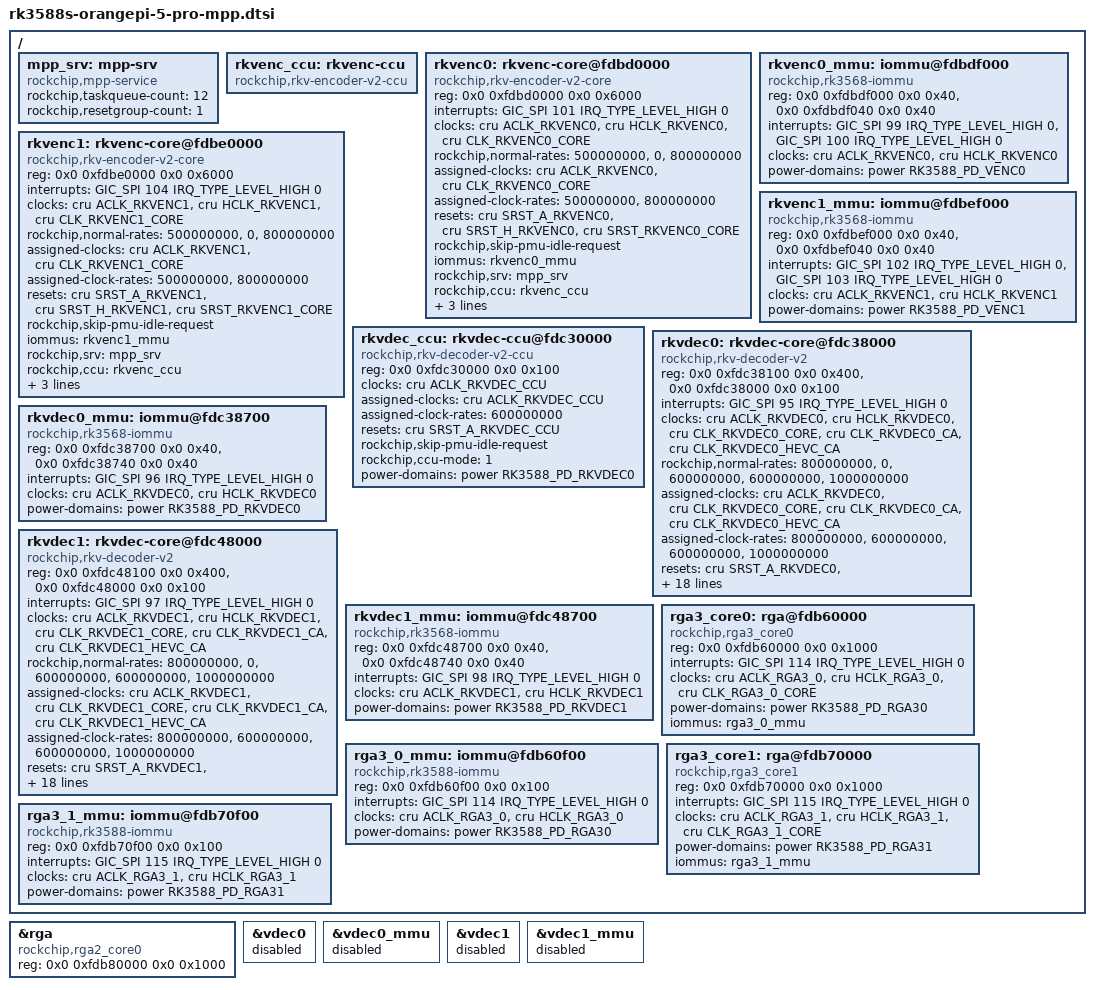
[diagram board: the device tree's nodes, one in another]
/*
 * opi5: the vendor MPP (RKVDEC2, RKVENC2) and multi-RGA nodes for the
 * zz-opi5-1xxx drivers. Included at the end of rk3588s-orangepi-5-pro.dts.
 */

/ {
	/*
	 * The rkmpp-codec profile owns these cores through Rockchip's request
	 * ABI.  Keep this binding here, rather than changing rk3588-base.dtsi:
	 * other RK3588 boards retain their upstream V4L2 topology.
	 */
	mpp_srv: mpp-srv {
		compatible = "rockchip,mpp-service";
		rockchip,taskqueue-count = <12>;
		rockchip,resetgroup-count = <1>;
		status = "okay";
	};

	rkvenc_ccu: rkvenc-ccu {
		compatible = "rockchip,rkv-encoder-v2-ccu";
		status = "okay";
	};

	rkvenc0: rkvenc-core@fdbd0000 {
		compatible = "rockchip,rkv-encoder-v2-core";
		reg = <0x0 0xfdbd0000 0x0 0x6000>;
		interrupts = <GIC_SPI 101 IRQ_TYPE_LEVEL_HIGH 0>;
		clocks = <&cru ACLK_RKVENC0>, <&cru HCLK_RKVENC0>,
			 <&cru CLK_RKVENC0_CORE>;
		clock-names = "aclk_vcodec", "hclk_vcodec", "clk_core";
		rockchip,normal-rates = <500000000>, <0>, <800000000>;
		assigned-clocks = <&cru ACLK_RKVENC0>, <&cru CLK_RKVENC0_CORE>;
		assigned-clock-rates = <500000000>, <800000000>;
		resets = <&cru SRST_A_RKVENC0>, <&cru SRST_H_RKVENC0>,
			 <&cru SRST_RKVENC0_CORE>;
		reset-names = "video_a", "video_h", "video_core";
		rockchip,skip-pmu-idle-request;
		iommus = <&rkvenc0_mmu>;
		rockchip,srv = <&mpp_srv>;
		rockchip,ccu = <&rkvenc_ccu>;
		rockchip,taskqueue-node = <7>;
		rockchip,task-capacity = <8>;
		power-domains = <&power RK3588_PD_VENC0>;
		status = "okay";
	};

	rkvenc0_mmu: iommu@fdbdf000 {
		compatible = "rockchip,rk3568-iommu";
		reg = <0x0 0xfdbdf000 0x0 0x40>, <0x0 0xfdbdf040 0x0 0x40>;
		interrupts = <GIC_SPI 99 IRQ_TYPE_LEVEL_HIGH 0>,
			     <GIC_SPI 100 IRQ_TYPE_LEVEL_HIGH 0>;
		clocks = <&cru ACLK_RKVENC0>, <&cru HCLK_RKVENC0>;
		clock-names = "aclk", "iface";
		#iommu-cells = <0>;
		power-domains = <&power RK3588_PD_VENC0>;
		status = "okay";
	};

	rkvenc1: rkvenc-core@fdbe0000 {
		compatible = "rockchip,rkv-encoder-v2-core";
		reg = <0x0 0xfdbe0000 0x0 0x6000>;
		interrupts = <GIC_SPI 104 IRQ_TYPE_LEVEL_HIGH 0>;
		clocks = <&cru ACLK_RKVENC1>, <&cru HCLK_RKVENC1>,
			 <&cru CLK_RKVENC1_CORE>;
		clock-names = "aclk_vcodec", "hclk_vcodec", "clk_core";
		rockchip,normal-rates = <500000000>, <0>, <800000000>;
		assigned-clocks = <&cru ACLK_RKVENC1>, <&cru CLK_RKVENC1_CORE>;
		assigned-clock-rates = <500000000>, <800000000>;
		resets = <&cru SRST_A_RKVENC1>, <&cru SRST_H_RKVENC1>,
			 <&cru SRST_RKVENC1_CORE>;
		reset-names = "video_a", "video_h", "video_core";
		rockchip,skip-pmu-idle-request;
		iommus = <&rkvenc1_mmu>;
		rockchip,srv = <&mpp_srv>;
		rockchip,ccu = <&rkvenc_ccu>;
		rockchip,taskqueue-node = <7>;
		rockchip,task-capacity = <8>;
		power-domains = <&power RK3588_PD_VENC1>;
		status = "okay";
	};

	rkvenc1_mmu: iommu@fdbef000 {
		compatible = "rockchip,rk3568-iommu";
		reg = <0x0 0xfdbef000 0x0 0x40>, <0x0 0xfdbef040 0x0 0x40>;
		interrupts = <GIC_SPI 102 IRQ_TYPE_LEVEL_HIGH 0>,
			     <GIC_SPI 103 IRQ_TYPE_LEVEL_HIGH 0>;
		clocks = <&cru ACLK_RKVENC1>, <&cru HCLK_RKVENC1>;
		clock-names = "aclk", "iface";
		#iommu-cells = <0>;
		power-domains = <&power RK3588_PD_VENC1>;
		status = "okay";
	};

	rkvdec_ccu: rkvdec-ccu@fdc30000 {
		compatible = "rockchip,rkv-decoder-v2-ccu";
		reg = <0x0 0xfdc30000 0x0 0x100>;
		reg-names = "ccu";
		clocks = <&cru ACLK_RKVDEC_CCU>;
		clock-names = "aclk_ccu";
		assigned-clocks = <&cru ACLK_RKVDEC_CCU>;
		assigned-clock-rates = <600000000>;
		resets = <&cru SRST_A_RKVDEC_CCU>;
		reset-names = "video_ccu";
		rockchip,skip-pmu-idle-request;
		rockchip,ccu-mode = <1>;
		power-domains = <&power RK3588_PD_RKVDEC0>;
		status = "okay";
	};

	rkvdec0: rkvdec-core@fdc38000 {
		compatible = "rockchip,rkv-decoder-v2";
		reg = <0x0 0xfdc38100 0x0 0x400>, <0x0 0xfdc38000 0x0 0x100>;
		reg-names = "regs", "link";
		interrupts = <GIC_SPI 95 IRQ_TYPE_LEVEL_HIGH 0>;
		clocks = <&cru ACLK_RKVDEC0>, <&cru HCLK_RKVDEC0>,
			 <&cru CLK_RKVDEC0_CORE>, <&cru CLK_RKVDEC0_CA>,
			 <&cru CLK_RKVDEC0_HEVC_CA>;
		clock-names = "aclk_vcodec", "hclk_vcodec", "clk_core",
			      "clk_cabac", "clk_hevc_cabac";
		rockchip,normal-rates = <800000000>, <0>, <600000000>,
					<600000000>, <1000000000>;
		assigned-clocks = <&cru ACLK_RKVDEC0>, <&cru CLK_RKVDEC0_CORE>,
				  <&cru CLK_RKVDEC0_CA>, <&cru CLK_RKVDEC0_HEVC_CA>;
		assigned-clock-rates = <800000000>, <600000000>,
				       <600000000>, <1000000000>;
		resets = <&cru SRST_A_RKVDEC0>, <&cru SRST_H_RKVDEC0>,
			 <&cru SRST_RKVDEC0_CORE>, <&cru SRST_RKVDEC0_CA>,
			 <&cru SRST_RKVDEC0_HEVC_CA>;
		reset-names = "video_a", "video_h", "video_core", "video_cabac",
			      "video_hevc_cabac";
		rockchip,skip-pmu-idle-request;
		/* Firmware reset preserves the RKVDEC2 CCU transaction. */
		rockchip,vpu-reset-smc;
		iommus = <&rkvdec0_mmu>;
		rockchip,srv = <&mpp_srv>;
		rockchip,ccu = <&rkvdec_ccu>;
		rockchip,core-mask = <0x00010001>;
		rockchip,task-capacity = <16>;
		rockchip,taskqueue-node = <9>;
		rockchip,sram = <&vdec0_sram>;
		rockchip,rcb-iova = <0xfff00000 0x100000>;
		rockchip,rcb-info = <136 24576>, <137 49152>, <141 90112>,
				    <140 49152>, <139 180224>, <133 49152>,
				    <134 8192>, <135 4352>, <138 13056>, <142 291584>;
		rockchip,rcb-min-width = <512>;
		power-domains = <&power RK3588_PD_RKVDEC0>;
		status = "okay";
	};

	rkvdec0_mmu: iommu@fdc38700 {
		compatible = "rockchip,rk3568-iommu";
		reg = <0x0 0xfdc38700 0x0 0x40>, <0x0 0xfdc38740 0x0 0x40>;
		interrupts = <GIC_SPI 96 IRQ_TYPE_LEVEL_HIGH 0>;
		clocks = <&cru ACLK_RKVDEC0>, <&cru HCLK_RKVDEC0>;
		clock-names = "aclk", "iface";
		#iommu-cells = <0>;
		power-domains = <&power RK3588_PD_RKVDEC0>;
		status = "okay";
	};

	rkvdec1: rkvdec-core@fdc48000 {
		compatible = "rockchip,rkv-decoder-v2";
		reg = <0x0 0xfdc48100 0x0 0x400>, <0x0 0xfdc48000 0x0 0x100>;
		reg-names = "regs", "link";
		interrupts = <GIC_SPI 97 IRQ_TYPE_LEVEL_HIGH 0>;
		clocks = <&cru ACLK_RKVDEC1>, <&cru HCLK_RKVDEC1>,
			 <&cru CLK_RKVDEC1_CORE>, <&cru CLK_RKVDEC1_CA>,
			 <&cru CLK_RKVDEC1_HEVC_CA>;
		clock-names = "aclk_vcodec", "hclk_vcodec", "clk_core",
			      "clk_cabac", "clk_hevc_cabac";
		rockchip,normal-rates = <800000000>, <0>, <600000000>,
					<600000000>, <1000000000>;
		assigned-clocks = <&cru ACLK_RKVDEC1>, <&cru CLK_RKVDEC1_CORE>,
				  <&cru CLK_RKVDEC1_CA>, <&cru CLK_RKVDEC1_HEVC_CA>;
		assigned-clock-rates = <800000000>, <600000000>,
				       <600000000>, <1000000000>;
		resets = <&cru SRST_A_RKVDEC1>, <&cru SRST_H_RKVDEC1>,
			 <&cru SRST_RKVDEC1_CORE>, <&cru SRST_RKVDEC1_CA>,
			 <&cru SRST_RKVDEC1_HEVC_CA>;
		reset-names = "video_a", "video_h", "video_core", "video_cabac",
			      "video_hevc_cabac";
		rockchip,skip-pmu-idle-request;
		/* Firmware reset preserves the RKVDEC2 CCU transaction. */
		rockchip,vpu-reset-smc;
		iommus = <&rkvdec1_mmu>;
		rockchip,srv = <&mpp_srv>;
		rockchip,ccu = <&rkvdec_ccu>;
		rockchip,core-mask = <0x00020002>;
		rockchip,task-capacity = <16>;
		rockchip,taskqueue-node = <9>;
		rockchip,sram = <&vdec1_sram>;
		rockchip,rcb-iova = <0xffe00000 0x100000>;
		rockchip,rcb-info = <136 24576>, <137 49152>, <141 90112>,
				    <140 49152>, <139 180224>, <133 49152>,
				    <134 8192>, <135 4352>, <138 13056>, <142 291584>;
		rockchip,rcb-min-width = <512>;
		power-domains = <&power RK3588_PD_RKVDEC1>;
		status = "okay";
	};

	rkvdec1_mmu: iommu@fdc48700 {
		compatible = "rockchip,rk3568-iommu";
		reg = <0x0 0xfdc48700 0x0 0x40>, <0x0 0xfdc48740 0x0 0x40>;
		interrupts = <GIC_SPI 98 IRQ_TYPE_LEVEL_HIGH 0>;
		clocks = <&cru ACLK_RKVDEC1>, <&cru HCLK_RKVDEC1>;
		clock-names = "aclk", "iface";
		#iommu-cells = <0>;
		power-domains = <&power RK3588_PD_RKVDEC1>;
		status = "okay";
	};

	rga3_core0: rga@fdb60000 {
		compatible = "rockchip,rga3_core0";
		reg = <0x0 0xfdb60000 0x0 0x1000>;
		interrupts = <GIC_SPI 114 IRQ_TYPE_LEVEL_HIGH 0>;
		interrupt-names = "rga3_core0_irq";
		clocks = <&cru ACLK_RGA3_0>, <&cru HCLK_RGA3_0>,
			 <&cru CLK_RGA3_0_CORE>;
		clock-names = "aclk_rga3_0", "hclk_rga3_0", "clk_rga3_0";
		power-domains = <&power RK3588_PD_RGA30>;
		iommus = <&rga3_0_mmu>;
		status = "okay";
	};

	rga3_0_mmu: iommu@fdb60f00 {
		compatible = "rockchip,rk3588-iommu", "rockchip,rk3568-iommu";
		reg = <0x0 0xfdb60f00 0x0 0x100>;
		interrupts = <GIC_SPI 114 IRQ_TYPE_LEVEL_HIGH 0>;
		interrupt-names = "rga3_0_mmu";
		clocks = <&cru ACLK_RGA3_0>, <&cru HCLK_RGA3_0>;
		clock-names = "aclk", "iface";
		power-domains = <&power RK3588_PD_RGA30>;
		#iommu-cells = <0>;
		status = "okay";
	};

	rga3_core1: rga@fdb70000 {
		compatible = "rockchip,rga3_core1";
		reg = <0x0 0xfdb70000 0x0 0x1000>;
		interrupts = <GIC_SPI 115 IRQ_TYPE_LEVEL_HIGH 0>;
		interrupt-names = "rga3_core1_irq";
		clocks = <&cru ACLK_RGA3_1>, <&cru HCLK_RGA3_1>,
			 <&cru CLK_RGA3_1_CORE>;
		clock-names = "aclk_rga3_1", "hclk_rga3_1", "clk_rga3_1";
		power-domains = <&power RK3588_PD_RGA31>;
		iommus = <&rga3_1_mmu>;
		status = "okay";
	};

	rga3_1_mmu: iommu@fdb70f00 {
		compatible = "rockchip,rk3588-iommu", "rockchip,rk3568-iommu";
		reg = <0x0 0xfdb70f00 0x0 0x100>;
		interrupts = <GIC_SPI 115 IRQ_TYPE_LEVEL_HIGH 0>;
		interrupt-names = "rga3_1_mmu";
		clocks = <&cru ACLK_RGA3_1>, <&cru HCLK_RGA3_1>;
		clock-names = "aclk", "iface";
		power-domains = <&power RK3588_PD_RGA31>;
		#iommu-cells = <0>;
		status = "okay";
	};
};

/*
 * The upstream V4L2 RGA2 node shares fdb80000 with the vendor multi-RGA
 * service.  Retarget that single node rather than creating a duplicate
 * unit-address node, then bind all three engines to one /dev/rga owner.
 */
&rga {
	compatible = "rockchip,rga2_core0";
	reg = <0x0 0xfdb80000 0x0 0x1000>;
	interrupt-names = "rga2_irq";
	clock-names = "aclk_rga2", "hclk_rga2", "clk_rga2";
	status = "okay";
};

/* The MPP binding owns the vendor decoder windows and IOMMU instances. */
&vdec0 {
	status = "disabled";
};

&vdec0_mmu {
	status = "disabled";
};

&vdec1 {
	status = "disabled";
};

&vdec1_mmu {
	status = "disabled";
};

/* Keep the MPP IOMMUs enabled after disabling the competing V4L2 nodes. */
&rkvdec0_mmu {
	status = "okay";
};

&rkvdec1_mmu {
	status = "okay";
};
